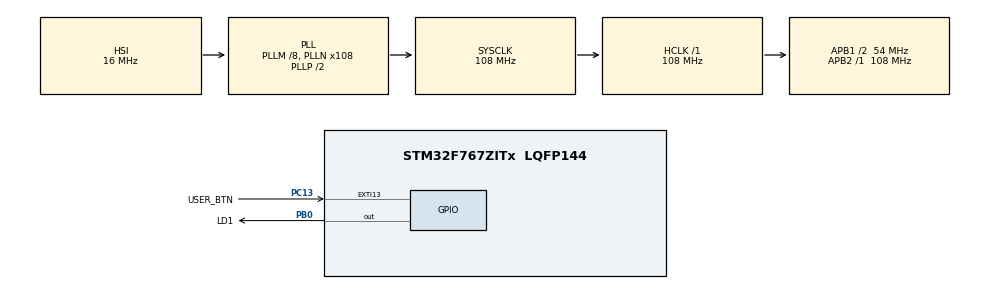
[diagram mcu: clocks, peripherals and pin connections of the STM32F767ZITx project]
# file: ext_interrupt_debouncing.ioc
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Mcu.Family=STM32F7
Mcu.Name=STM32F767ZITx
Mcu.Package=LQFP144
NVIC.EXTI15_10_IRQn=true\:0\:0\:false\:false\:true\:true\:true\:true
NVIC.PriorityGroup=NVIC_PRIORITYGROUP_4
PB0.GPIO_Label=LD1
PB0.Signal=GPIO_Output
PC13.GPIO_Label=USER_BTN
PC13.Signal=GPXTI13
PH0/OSC_IN.Mode=HSE-External-Oscillator
PH0/OSC_IN.Signal=RCC_OSC_IN
PH1/OSC_OUT.Mode=HSE-External-Oscillator
PH1/OSC_OUT.Signal=RCC_OSC_OUT
ProjectManager.HeapSize=0x200
ProjectManager.StackSize=0x400
ProjectManager.TargetToolchain=STM32CubeIDE
RCC.48MHZClocksFreq_Value=24000000
RCC.AHBFreq_Value=108000000
RCC.APB1CLKDivider=RCC_HCLK_DIV2
RCC.APB1Freq_Value=54000000
RCC.APB1TimFreq_Value=108000000
RCC.APB2Freq_Value=108000000
RCC.APB2TimFreq_Value=108000000
RCC.CortexFreq_Value=108000000
RCC.HCLKFreq_Value=108000000
RCC.HSE_VALUE=8000000
RCC.HSI_VALUE=16000000
RCC.LSE_VALUE=32768
RCC.PLLM=8
RCC.PLLMUL=RCC_PLL_MUL9
RCC.PLLN=108
RCC.PRESCALERUSB=RCC_USBCLKSOURCE_PLL_DIV1_5
RCC.SYSCLKFreq_VALUE=108000000
RCC.SYSCLKSource=RCC_SYSCLKSOURCE_PLLCLK
RCC.SYSCLKSourceVirtual=RCC_SYSCLKSOURCE_PLLCLK
RCC.USBFreq_Value=108000000
RCC.VCOOutputFreq_Value=216000000
board=NUCLEO-F767ZI

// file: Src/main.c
/* USER CODE BEGIN Header */
/**
  ******************************************************************************
  * @file           : main.c
  * @brief          : Main program body
  ******************************************************************************
  * @attention
  *
  * Copyright (c) 2025 STMicroelectronics.
  * All rights reserved.
  *
  * This software is licensed under terms that can be found in the LICENSE file
  * in the root directory of this software component.
  * If no LICENSE file comes with this software, it is provided AS-IS.
  *
  ******************************************************************************
  */
/* USER CODE END Header */
#include "main.h"

/* USER CODE BEGIN PV */
// --- Global Variables for Debouncing ---
volatile uint32_t lastDebounceTime = 0;
const uint32_t debounceDelay = 10; // 10 milliseconds

/* USER CODE END PV */

void SystemClock_Config(void);
static void MX_GPIO_Init(void);

int main(void)
{

  /* MCU Configuration--------------------------------------------------------*/

  /* Reset of all peripherals, Initializes the Flash interface and the Systick. */
  HAL_Init();

  /* Configure the system clock */
  SystemClock_Config();

  /* Initialize all configured peripherals */
  MX_GPIO_Init();

  /* Infinite loop */
  while (1)
  {

  }
}

void SystemClock_Config(void)
{
  RCC_OscInitTypeDef RCC_OscInitStruct = {0};
  RCC_ClkInitTypeDef RCC_ClkInitStruct = {0};

  /** Configure the main internal regulator output voltage
  */
  __HAL_RCC_PWR_CLK_ENABLE();
  __HAL_PWR_VOLTAGESCALING_CONFIG(PWR_REGULATOR_VOLTAGE_SCALE3);

  /** Initializes the RCC Oscillators according to the specified parameters
  * in the RCC_OscInitTypeDef structure.
  */
  RCC_OscInitStruct.OscillatorType = RCC_OSCILLATORTYPE_HSI;
  RCC_OscInitStruct.HSIState = RCC_HSI_ON;
  RCC_OscInitStruct.HSICalibrationValue = RCC_HSICALIBRATION_DEFAULT;
  RCC_OscInitStruct.PLL.PLLState = RCC_PLL_ON;
  RCC_OscInitStruct.PLL.PLLSource = RCC_PLLSOURCE_HSI;
  RCC_OscInitStruct.PLL.PLLM = 8;
  RCC_OscInitStruct.PLL.PLLN = 108;
  RCC_OscInitStruct.PLL.PLLP = RCC_PLLP_DIV2;
  RCC_OscInitStruct.PLL.PLLQ = 2;
  RCC_OscInitStruct.PLL.PLLR = 2;
  if (HAL_RCC_OscConfig(&RCC_OscInitStruct) != HAL_OK)
  {
    Error_Handler();
  }

  /** Activate the Over-Drive mode
  */
  if (HAL_PWREx_EnableOverDrive() != HAL_OK)
  {
    Error_Handler();
  }

  /** Initializes the CPU, AHB and APB buses clocks
  */
  RCC_ClkInitStruct.ClockType = RCC_CLOCKTYPE_HCLK|RCC_CLOCKTYPE_SYSCLK
                              |RCC_CLOCKTYPE_PCLK1|RCC_CLOCKTYPE_PCLK2;
  RCC_ClkInitStruct.SYSCLKSource = RCC_SYSCLKSOURCE_PLLCLK;
  RCC_ClkInitStruct.AHBCLKDivider = RCC_SYSCLK_DIV1;
  RCC_ClkInitStruct.APB1CLKDivider = RCC_HCLK_DIV2;
  RCC_ClkInitStruct.APB2CLKDivider = RCC_HCLK_DIV1;

  if (HAL_RCC_ClockConfig(&RCC_ClkInitStruct, FLASH_LATENCY_3) != HAL_OK)
  {
    Error_Handler();
  }
}

static void MX_GPIO_Init(void)
{
  GPIO_InitTypeDef GPIO_InitStruct = {0};

  /* GPIO Ports Clock Enable */
  __HAL_RCC_GPIOC_CLK_ENABLE();
  __HAL_RCC_GPIOH_CLK_ENABLE();
  __HAL_RCC_GPIOB_CLK_ENABLE();

  /*Configure GPIO pin Output Level */
  HAL_GPIO_WritePin(LD1_GPIO_Port, LD1_Pin, GPIO_PIN_RESET);

  /*Configure GPIO pin : USER_BTN_Pin */
  GPIO_InitStruct.Pin = USER_BTN_Pin;
  GPIO_InitStruct.Mode = GPIO_MODE_IT_RISING;
  GPIO_InitStruct.Pull = GPIO_NOPULL;
  HAL_GPIO_Init(USER_BTN_GPIO_Port, &GPIO_InitStruct);

  /*Configure GPIO pin : LD1_Pin */
  GPIO_InitStruct.Pin = LD1_Pin;
  GPIO_InitStruct.Mode = GPIO_MODE_OUTPUT_PP;
  GPIO_InitStruct.Pull = GPIO_NOPULL;
  GPIO_InitStruct.Speed = GPIO_SPEED_FREQ_LOW;
  HAL_GPIO_Init(LD1_GPIO_Port, &GPIO_InitStruct);

  /* EXTI interrupt init*/
  HAL_NVIC_SetPriority(EXTI15_10_IRQn, 0, 0);
  HAL_NVIC_EnableIRQ(EXTI15_10_IRQn);

}

/* USER CODE BEGIN 4 */

void HAL_GPIO_EXTI_Callback(uint16_t GPIO_Pin){
   if(GPIO_Pin == GPIO_PIN_13){ // Check whether the interrupt source is EXTI Line13 (PC13 Pin)
    // Get the current tick time
    uint32_t currentTime = HAL_GetTick();
    // Check if enough time has passed since the last valid press
    if ((currentTime - lastDebounceTime) > debounceDelay){
      // If yes, this is a valid button press/release
      HAL_GPIO_TogglePin(LD1_GPIO_Port, LD1_Pin);

      // Update the last debounce time
      lastDebounceTime = currentTime;
    }
    // If not enough time has passed, ignore this interrupt (it's bounce)
  }
}

/* USER CODE END 4 */

void Error_Handler(void)
{
  __disable_irq();
  while (1)
  {
  }
}
